# NANO103AE_v1 register map
File version: 1.0
Registers are 32-bit, read-write, reset 0x0 unless marked. A register's access mark holds for its fields unless they carry their own. Offsets are from the block's base; [hi:lo] are bit positions; {n}, {i} and the like mark numbered series.

## FMC — FMC Register Map
Base 0x5000C000
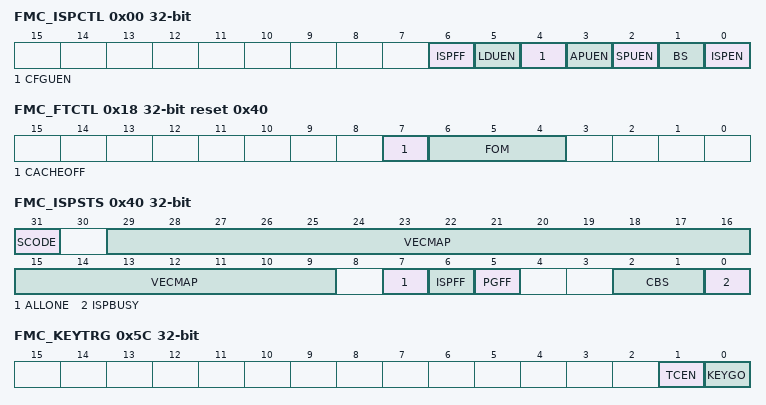
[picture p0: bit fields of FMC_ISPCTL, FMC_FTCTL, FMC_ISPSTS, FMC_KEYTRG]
0x00 FMC_ISPCTL — ISP Control Register
  [6] ISPFF — ISP Fail Flag (Write Protect). This bit is set by hardware when a triggered ISP meets any of the following conditions: This bit needs to be cleared by writing 1 to it. (1) APROM writes to itself if APUEN is set to 0. (2) LDROM writes to itself if LDUEN is set to 0. (3) CONFIG is erased/programmed if CFGUEN is set to 0. (4) SPROM is erased/programmed if SPUEN is set to 0 (5) SPROM is programmed at SPROM secured mode. (6) Page Erase command at LOCK mode with ICE connection (7) Erase or Program command at brown-out detected (8) Destination address is illegal, such as over an available range. (9) Invalid ISP commands (10) Vector address is mapping to SPROM region (11) KPROM is erased/programmed if KEYLOCK is set to 1 (12) APROM(not include Data Flash) is erased/programmed if KEYLOCK is set to 1. Note: This bit is write protected. Refer to the SYS_REGLCTL register.
  [5] LDUEN — LDROM Update Enable Bit (Write Protect). LDROM update enable bit. Note: This bit is write protected. Refer to the SYS_REGLCTL register.
    0=LDROM cannot be updated; 1=LDROM can be updated
  [4] CFGUEN — CONFIG Update Enable Bit (Write Protect). Note: This bit is write protected. Refer to the SYS_REGLCTL register.
    0=CONFIG cannot be updated; 1=CONFIG can be updated
  [3] APUEN — APROM Update Enable Bit (Write Protect). Note: This bit is write protected. Refer to the SYS_REGLCTL register.
    0=APROM cannot be updated when the chip runs in APROM; 1=APROM can be updated when the chip runs in APROM
  [2] SPUEN — SPROM Update Enable Bit (Write Protect). Note: This bit is write protected. Refer to the SYS_REGLCTL register.
    0=SPROM cannot be updated; 1=SPROM can be updated
  [1] BS — Boot Select (Write Protect). Set/clear this bit to select next booting from LDROM/APROM, respectively. This bit also functions as chip booting status flag, which can be used to check where chip booted from. This bit is initiated with the inversed value of CBS[1] (CONFIG0[7]) after any reset is happened except CPU reset (CPU is 1) or system reset (SYS) is happened. Note: This bit is write protected. Refer to the SYS_REGLCTL register.
    0=Booting from APROM; 1=Booting from LDROM
  [0] ISPEN — ISP Enable Bit (Write Protect). ISP function enable bit. Set this bit to enable ISP function. Note: This bit is write protected. Refer to the SYS_REGLCTL register.
    0=ISP function Disabled; 1=ISP function Enabled
0x04 FMC_ISPADDR — ISP Address Register
  [31:0] ISPADDR — ISP Address. The Nano103 series is equipped with embedded flash. ISPADDR [1:0] must be kept 00 for ISP 32-bit operation. For both CRC-32 Checksum Calculation and Flash All-One Verification commands, this field is the flash starting address for checksum calculation and 512 bytes address alignment is necessary.
0x08 FMC_ISPDAT — ISP Data Register
  [31:0] ISPDAT — ISP Data. Write data to this register before ISP program operation. Read data from this register after ISP read operation.
0x0C FMC_ISPCMD — ISP CMD Register
  [5:0] CMD — ISP CMD. ISP command table is shown below: The other commands are invalid.
    0=FLASH 32-bit Read; 4=Read Unique ID; 8=Read All-One Verification Result; 11=Read Company ID; 12=Read Device ID; 13=Read Checksum; 33=FLASH 32-bit Program; 34=FLASH Page Erase; 38=FLASH Mass Erase; 40=Run All-One Verification; 45=Run CRC-32 Checksum Calculation; 46=Vector Remap
0x10 FMC_ISPTRG — ISP Trigger Control Register
  [0] ISPGO — ISP Start Trigger (Write Protect). Write 1 to start ISP operation and this bit will be cleared to 0 by hardware automatically when ISP operation is finished. Note:This bit is write protected. Refer to the SYS_REGLCTL register.
    0=ISP operation is finished; 1=ISP is progressed
0x14 FMC_DFBA ro reset not defined — Data Flash Base Address
  [31:0] DFBA — Data Flash Base Address. This register indicates Data Flash start address. It is a read only register. The Data Flash is shared with APROM. the content of this register is loaded from CONFIG1
0x18 FMC_FTCTL reset 0x40 — Flash Access Time Control Register
  [7] CACHEOFF — Flash Cache Disable Control (Write Protect). Note:This bit is write protected. Refer to the SYS_REGLCTL register.
    0=Flash Cache function Enabled (default); 1=Flash Cache function Disabled
  [6:4] FOM — Frequency Optimization Mode (Write Protect). The Nano103 series supports adjustable flash access timing to optimize the flash access cycles in different working frequency. Note:This bit is write protected. Refer to the SYS_REGLCTL register.
    1=Frequency 20MHz; 4=Frequency 40MHz. (default power-on setting)
0x40 FMC_ISPSTS — ISP Status Register
  [31] SCODE — Security Code Active Flag. This bit is set by hardware when detecting SPROM secured code is active at flash initiation, or software writes 1 to this bit to make secured code active; this bit is clear by SPROM page erase operation.
    0=Secured code is inactive; 1=Secured code is active
  [29:9] VECMAP ro — Vector Page Mapping Address (Read Only). All access to 0x0000_0000~0x0000_01FF is remapped to the flash memory or SRAM address {VECMAP[20:0], 9'h000} ~ {VECMAP[20:0], 9'h1FF} VECMAP [18:12] should be 0.
  [7] ALLONE — Flash All-one Verification Flag. This bit is set by hardware if all of flash bits are 1, and clear if flash bits are not all 1 after "Run Flash All-One Verification" complete; this bit also can be clear by writing 1
    0=All of flash bits are 1 after "Run Flash All-One Verification" complete; 1=Flash bits are not all 1 after "Run Flash All-One Verification" complete
  [6] ISPFF — ISP Fail Flag (Write Protect). This bit is the mirror of ISPFF (FMC_ISPCTL[6]), it needs to be cleared by writing 1 to FMC_ISPCTL[6] or FMC_ISPSTS[6]. This bit is set by hardware when a triggered ISP meets any of the following conditions: (1) APROM writes to itself if APUEN is set to 0. (2) LDROM writes to itself if LDUEN is set to 0. (3) CONFIG is erased/programmed if CFGUEN is set to 0. (4) SPROM is erased/programmed if SPUEN is set to 0 (5) SPROM is programmed at SPROM secured mode. (6) Page Erase command at LOCK mode with ICE connection (7) Erase or Program command at brown-out detected (8) Destination address is illegal, such as over an available range. (9) Invalid ISP commands (10) Vector address is mapping to SPROM region (11) KPROM is erased/programmed if KEYLOCK is set to 1 (12) APROM(not include Data Flash) is erased/programmed if KEYLOCK is set to 1. Note: This bit is write-protected. Refer to the SYS_REGLCTL register.
  [5] PGFF ro — Flash Program with Fast Verification Flag(Read Only). This bit is set if data is mismatched at ISP programming verification. This bit is clear by performing ISP flash erase or ISP read CID operation
    0=Flash Program is success; 1=Flash Program is fail. Program data is different with data in the flash memory
  [2:1] CBS ro — Boot Selection of CONFIG (Read Only). This bit is initiated with the CBS (CONFIG0 [7:6]) after any reset is happened except CPU reset (CPU is 1) or system reset (SYS) is happened.
    0=LDROM with IAP mode; 1=LDROM without IAP mode; 2=APROM with IAP mode; 3=APROM without IAP mode
  [0] ISPBUSY ro — ISP Busy Flag (Read Only). Write 1 to start ISP operation and this bit will be cleared to 0 by hardware automatically when ISP operation is finished. This bit is the mirror of ISPGO(FMC_ISPTRG[0]).
    0=ISP operation is finished; 1=ISP is progressed
{0x50+4i} FMC_KEY{i} wo (i=0..2) — KEY{i} Data Register
  [31:0] KEY{i} — KEY{i} Data (Write Only). Write KEY{i} data to this register before KEY Comparison operation.
0x5C FMC_KEYTRG — KEY Comparison Trigger Control Register
  [1] TCEN — Time-out Counting Enable Bit (Write Protection). 10 minutes is at least for time-out, and average is about 20 minutes. Note:This bit is write-protected. Refer to the SYS_REGLCTL register.
    0=Time-out counting Disabled; 1=Time-out counting Enabled if key is matched after key comparison finish
  [0] KEYGO — KEY Comparison Start Trigger (Write Protection). Write 1 to start KEY comparison operation and this bit will be cleared to 0 by hardware automatically when KEY comparison operation is finished. This trigger operation is valid while FORBID (FMC_KEYSTS [3]) is 0. Note:This bit is write-protected. Refer to the SYS_REGLCTL register.
    0=KEY comparison operation is finished; 1=KEY comparison is progressed
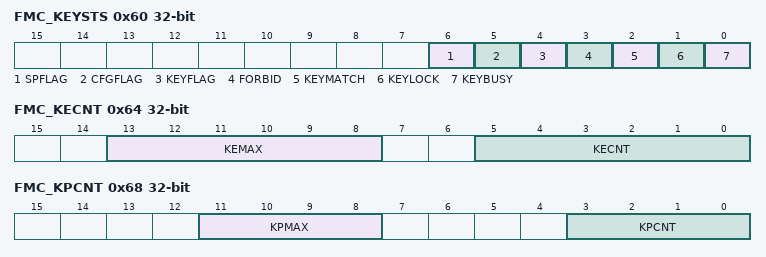
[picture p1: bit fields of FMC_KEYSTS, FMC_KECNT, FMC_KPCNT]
0x60 FMC_KEYSTS — KEY Comparison Status Register
  [6] SPFLAG ro — SPROM Write-protection Enable Flag(Read Only). This bit is set while the KEYENROM [1] is 0 at power-on or reset. This bit is cleared to 0 by hardware while KPROM is erased. This bit is set to 1 by hardware while KEYENROM[1] is programmed to 0.
    0=SPROM write-protection Disabled; 1=SPROM write-protection Enabled
  [5] CFGFLAG ro — CONFIG Write-protection Enable Flag(Read Only). This bit is set while the KEYENROM [0] is 0 at power-on or reset. This bit is cleared to 0 by hardware while KPROM is erased. This bit is set to 1 by hardware while KEYENROM[0] is programmed to 0.
    0=CONFIG write-protection Disabled; 1=CONFIG write-protection Enabled
  [4] KEYFLAG ro — KEY Protection Enable Flag(Read Only). This bit is set while the KEYENROM [7:0] is not 0xFF at power-on or reset. This bit is cleared to 0 by hardware while KPROM is erased. This bit is set to 1 by hardware while KEYENROM is programmed to a non-0xFF value.
    0=Security Key protection Disabled; 1=Security KeyprotectionEnabled
  [3] FORBID ro — KEY Comparison Forbidden Flag(Read Only). This bit is set to 1 whenKECNT(FMC_KECNT[4:0])is more than KEMAX (FMC_KECNT[12:8]) orKPCNT (FMC_KPCNT [2:0])is more than KPMAX (FMC_KPCNT [10:8]).
    0=KEY comparison is not forbidden; 1=KEY comparison is forbidden, KEYGO (FMC_KEYTRG [0]) cannot trigger
  [2] KEYMATCH ro — KEY Match Flag(Read Only). This bit is set to 1 after KEY comparison complete if the KEY0, KEY1 and KEY2 are matched with the 96-bit security keys in KPROM; and cleared to 0 if KEYs are unmatched. This bit is also cleared to 0 while. CPU writing 1 to KEYLOCK(FMC_KEYSTS[1]) or. Time-out event or. KPROM is erased or. KEYENROM is programmed to a non-0xFF value. Chip is in Power-down mode.
    0=KEY0, KEY1, and KEY2 are unmatched with the KPROM setting; 1=KEY0, KEY1, and KEY2 are matched with the KPROM setting
  [1] KEYLOCK — KEY LOCK Flag. This bit is set to 1 if KEYMATCH (FMC_KEYSTS [2]) is 0 and cleared to 0 if KEYMATCH is 1 in Security Key protection. This bit also can be set to 1 while. CPU write 1 to KEYLOCK(FMC_KEYSTS[1]) or. KEYFLAG(FMC_KEYSTS[4]) is 1 at power-on or reset or. KEYENROM is programmed a non-0xFF value or. Time-out event or. FORBID(FMC_KEYSTS[3]) is 1. SPROM write protect is depended on SPFLAG. CONFIG write protect is depended on CFGFLAG
    0=KPROM and APROM (not include Data Flash) is not in write protection; 1=KPROM and APROM (not include Data Flash) is in write protection
  [0] KEYBUSY ro — KEY Comparison Busy (Read Only)
    0=KEY comparison is finished; 1=KEY comparison is busy
0x64 FMC_KECNT ro (reset mask 0xFFFF00FF) — KEY-Unmatched Counting Register
  [13:8] KEMAX — Maximum Number for Error Key Entry at Each Power-on (Read Only). KEMAX is the maximum error key entry number at each power-on. When KEMAXROM of KPROM is erased or programmed, KEMAX will also be updated. KEMAX is used to limit KECNT(FMC_KECNT[5:0]) maximum counting. The FORBID (FMC_KEYSTS [3]) will be set to 1 when KECNT is more than KEMAX.
  [5:0] KECNT — Error Key Entry Counter at Each Power-on (Read Only). KECNT is increased when entry keys is wrong in Security Key protection. KECNT is cleared to 0 if key comparison is matched or system power-on.
0x68 FMC_KPCNT ro (reset mask 0xFFFFF0FF) — KEY-Unmatched Power-on Counting Register
  [11:8] KPMAX — Power-on Maximum Number for Error Key Entry (Read Only). KPMAX is the power-on maximum number for error key entry. When KPMAXROM of KPROM is erased or programmed, KPMAX will also be updated. KPMAX is used to limit KPCNT (FMC_KPCNT [3:0]) maximum counting. The FORBID(FMC_KEYSTS[3]) will be set to 1 when KPCNT is more than KPMAX
  [3:0] KPCNT — Power-on Counter for Error Key Entry(Read Only). KPCNT is the power-on counting for error key entry in Security Key protection. KPCNT is cleared to 0 if key comparison is matched.
